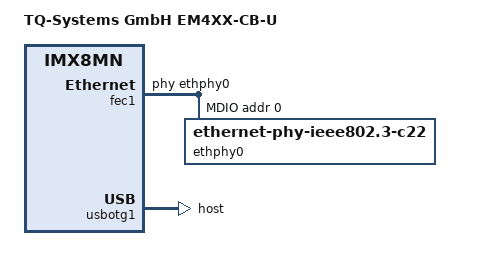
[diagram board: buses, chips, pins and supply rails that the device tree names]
// SPDX-License-Identifier: GPL-2.0+
/*
 * Copyright 2020 TQ Systems GmbH
 */

#include "fsl-imx8mn-em4xx.dtsi"

/ {
	model = "TQ-Systems GmbH EM4XX-CB-U";
};

&fec1 {
        status = "okay";
        phy-handle = <&ethphy0>;

	mdio {
		#address-cells = <1>;
		#size-cells = <0>;

		ethphy0: ethernet-phy@0 {
			compatible = "ethernet-phy-ieee802.3-c22";
			reg = <0>;
		};
	};
};

&usbotg1 {
	dr_mode = "host";
	disable-over-current;
	status = "okay";
};
